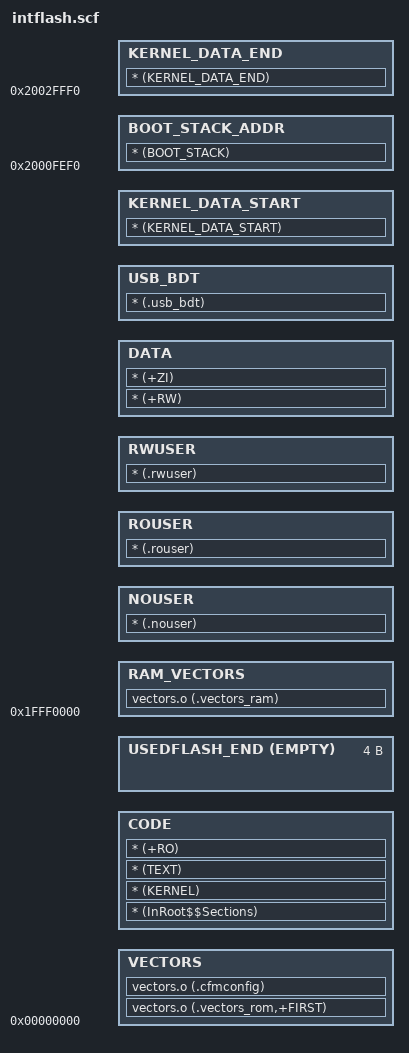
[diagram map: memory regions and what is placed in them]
#! armcc -E

#define INTFLASH_END_ADDR       0x00100000
#define INTFLASH_BASE_ADDR      0x00000000
#define INTFLASH_SIZE           (INTFLASH_END_ADDR - INTFLASH_BASE_ADDR)
#define FLASHX_SECT_SIZE        (0x1000)

#define MY_ALIGN(address, alignment) ((address + (alignment-1)) AND ~(alignment-1))

LOAD_REGION_INTFLASH INTFLASH_BASE_ADDR INTFLASH_SIZE
{
    VECTORS INTFLASH_BASE_ADDR
    {
        vectors.o (.vectors_rom,+FIRST)
        vectors.o (.cfmconfig)
    }

    CODE +0
    {
        * (InRoot$$Sections)      ; All library sections for example, __main.o,
                                  ; __scatter*.o, __dc*.o, and * Region$$Table
        * (KERNEL)
        * (TEXT)
        * (+RO)
    }

    USEDFLASH_END MY_ALIGN(ImageLimit(CODE), FLASHX_SECT_SIZE) EMPTY 0x4
    {
    }

    RAM_VECTORS 0x1FFF0000 ; For ram vector table. Used when  MQX_ROM_VECTORS is set to zero.
    {
        vectors.o (.vectors_ram)
    }
 
    NOUSER +0
    {
        * (.nouser)
    }

    ROUSER +0
    {
        * (.rouser)
    }

    RWUSER +0
    {
        * (.rwuser)
    }

    DATA +0
    {
        * (+RW)
        * (+ZI)
    }

    USB_BDT MY_ALIGN(ImageLimit(DATA), 512)
    {
        * (.usb_bdt)
    }

    KERNEL_DATA_START MY_ALIGN(ImageLimit(USB_BDT), 0x10)
    {
        * (KERNEL_DATA_START)     ; start of kernel data
    }

    KERNEL_DATA_END 0x2002FFF0      ; RAM_END
    {
        * (KERNEL_DATA_END)     ; end of kernel data
    }

    ; mem_init writes a storeblock_struct at the end of kernel data,
    ; max size 32 bytes, so use 0x100 offset
    BOOT_STACK_ADDR 0x2000FEF0
    {
        * (BOOT_STACK)
    }
}
